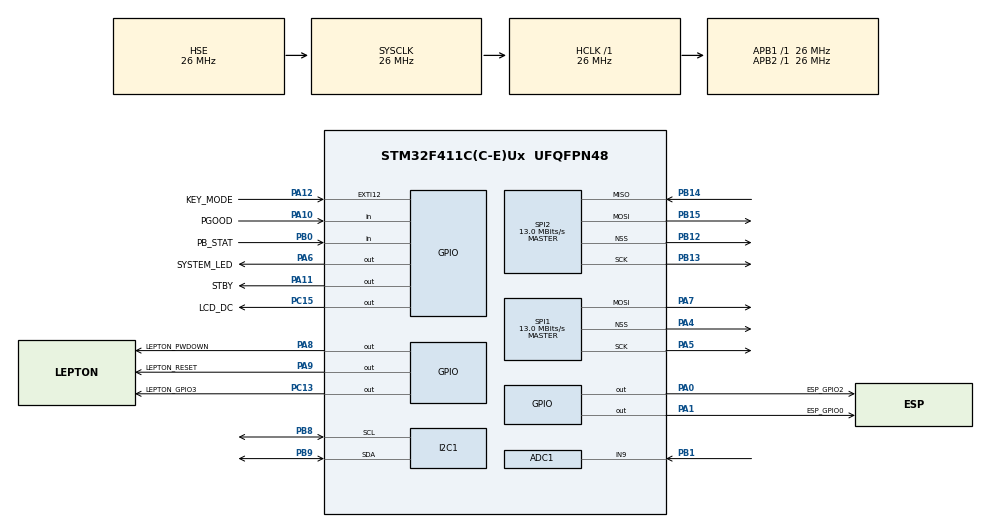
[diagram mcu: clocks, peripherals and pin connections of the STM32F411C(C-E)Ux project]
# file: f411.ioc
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ADC1.Channel-17\#ChannelRegularConversion=ADC_CHANNEL_9
ADC1.ClockPrescaler=ADC_CLOCK_SYNC_PCLK_DIV2
ADC1.ContinuousConvMode=DISABLE
ADC1.DMAContinuousRequests=DISABLE
ADC1.DataAlign=ADC_DATAALIGN_RIGHT
ADC1.DiscontinuousConvMode=DISABLE
ADC1.EOCSelection=ADC_EOC_SINGLE_CONV
ADC1.EnableAnalogWatchDog=false
ADC1.ExternalTrigConvEdge=ADC_EXTERNALTRIGCONVEDGE_NONE
ADC1.InjNumberOfConversion=0
ADC1.NbrOfConversion=1
ADC1.NbrOfConversionFlag=1
ADC1.Rank-17\#ChannelRegularConversion=1
ADC1.Resolution=ADC_RESOLUTION_12B
ADC1.SamplingTime-17\#ChannelRegularConversion=ADC_SAMPLETIME_3CYCLES
ADC1.ScanConvMode=DISABLE
ADC1.master=1
Dma.Request0=SPI2_TX
Dma.Request1=SPI1_TX
Dma.SPI1_TX.1.Direction=DMA_MEMORY_TO_PERIPH
Dma.SPI1_TX.1.FIFOMode=DMA_FIFOMODE_DISABLE
Dma.SPI1_TX.1.Instance=DMA2_Stream2
Dma.SPI1_TX.1.MemDataAlignment=DMA_MDATAALIGN_BYTE
Dma.SPI1_TX.1.MemInc=DMA_MINC_ENABLE
Dma.SPI1_TX.1.Mode=DMA_NORMAL
Dma.SPI1_TX.1.PeriphDataAlignment=DMA_PDATAALIGN_BYTE
Dma.SPI1_TX.1.PeriphInc=DMA_PINC_DISABLE
Dma.SPI1_TX.1.Priority=DMA_PRIORITY_LOW
Dma.SPI2_TX.0.Direction=DMA_MEMORY_TO_PERIPH
Dma.SPI2_TX.0.FIFOMode=DMA_FIFOMODE_DISABLE
Dma.SPI2_TX.0.Instance=DMA1_Stream4
Dma.SPI2_TX.0.MemDataAlignment=DMA_MDATAALIGN_HALFWORD
Dma.SPI2_TX.0.MemInc=DMA_MINC_ENABLE
Dma.SPI2_TX.0.Mode=DMA_NORMAL
Dma.SPI2_TX.0.PeriphDataAlignment=DMA_PDATAALIGN_HALFWORD
Dma.SPI2_TX.0.PeriphInc=DMA_PINC_DISABLE
Dma.SPI2_TX.0.Priority=DMA_PRIORITY_LOW
Mcu.Family=STM32F4
Mcu.Name=STM32F411C(C-E)Ux
Mcu.Package=UFQFPN48
NVIC.DMA1_Stream4_IRQn=true\:0\:0\:false\:false\:true
NVIC.DMA2_Stream2_IRQn=true\:0\:0\:false\:false\:true
NVIC.EXTI15_10_IRQn=true\:1\:2\:true\:false\:true
NVIC.PriorityGroup=NVIC_PRIORITYGROUP_2
NVIC.TIM2_IRQn=true\:2\:2\:true\:false\:true
PA0-WKUP.GPIO_Label=ESP_GPIO2
PA0-WKUP.Signal=GPIO_Output
PA1.GPIO_Label=ESP_GPIO0
PA1.Signal=GPIO_Output
PA10.GPIO_Label=PGOOD
PA10.Signal=GPIO_Input
PA11.GPIO_Label=STBY
PA11.Signal=GPIO_Output
PA12.GPIO_Label=KEY_MODE
PA12.GPIO_ModeDefaultEXTI=GPIO_MODE_IT_RISING_FALLING
PA12.GPIO_PuPd=GPIO_NOPULL
PA12.Signal=GPXTI12
PA13.Mode=Serial_Wire
PA13.Signal=SYS_JTMS-SWDIO
PA14.Mode=Serial_Wire
PA14.Signal=SYS_JTCK-SWCLK
PA4.Mode=NSS_Signal_Hard_Output
PA4.Signal=SPI1_NSS
PA5.Mode=TX_Only_Simplex_Unidirect_Master
PA5.Signal=SPI1_SCK
PA6.GPIO_Label=SYSTEM_LED
PA6.Signal=GPIO_Output
PA7.Mode=TX_Only_Simplex_Unidirect_Master
PA7.Signal=SPI1_MOSI
PA8.GPIO_Label=LEPTON_PWDOWN
PA8.Signal=GPIO_Output
PA9.GPIO_Label=LEPTON_RESET
PA9.Signal=GPIO_Output
PB0.GPIO_Label=PB_STAT
PB0.Signal=GPIO_Input
PB1.Signal=ADCx_IN9
PB12.Mode=NSS_Signal_Hard_Output
PB12.Signal=SPI2_NSS
PB13.Mode=Full_Duplex_Master
PB13.Signal=SPI2_SCK
PB14.Mode=Full_Duplex_Master
PB14.Signal=SPI2_MISO
PB15.Mode=Full_Duplex_Master
PB15.Signal=SPI2_MOSI
PB8.Mode=I2C
PB8.Signal=I2C1_SCL
PB9.Mode=I2C
PB9.Signal=I2C1_SDA
PC13-ANTI_TAMP.GPIO_Label=LEPTON_GPIO3
PC13-ANTI_TAMP.Signal=GPIO_Output
PC15-OSC32_OUT.GPIO_Label=LCD_DC
PC15-OSC32_OUT.Signal=GPIO_Output
PH0\ -\ OSC_IN.Mode=HSE-External-Oscillator
PH0\ -\ OSC_IN.Signal=RCC_OSC_IN
PH1\ -\ OSC_OUT.Mode=HSE-External-Oscillator
PH1\ -\ OSC_OUT.Signal=RCC_OSC_OUT
ProjectManager.HeapSize=0x200
ProjectManager.StackSize=0x400
ProjectManager.TargetToolchain=MDK-ARM V5
RCC.48MHZClocksFreq_Value=78000000
RCC.AHBFreq_Value=26000000
RCC.APB1Freq_Value=26000000
RCC.APB1TimFreq_Value=26000000
RCC.APB2Freq_Value=26000000
RCC.APB2TimFreq_Value=26000000
RCC.CortexFreq_Value=26000000
RCC.HCLKFreq_Value=26000000
RCC.HSE_VALUE=26000000
RCC.HSI_VALUE=16000000
RCC.LSE_VALUE=32768
RCC.PLLSourceVirtual=RCC_PLLSOURCE_HSE
RCC.SYSCLKFreq_VALUE=26000000
RCC.SYSCLKSource=RCC_SYSCLKSOURCE_HSE
RCC.VCOOutputFreq_Value=312000000
SH.ADCx_IN9.0=ADC1_IN9,IN9
SPI1.CalculateBaudRate=13.0 MBits/s
SPI1.Mode=SPI_MODE_MASTER
SPI1.VirtualNSS=VM_NSSHARD
SPI2.CLKPhase=SPI_PHASE_2EDGE
SPI2.CLKPolarity=SPI_POLARITY_HIGH
SPI2.CalculateBaudRate=13.0 MBits/s
SPI2.DataSize=SPI_DATASIZE_16BIT
SPI2.Mode=SPI_MODE_MASTER
SPI2.VirtualNSS=VM_NSSHARD
TIM2.Period=9
TIM2.Prescaler=2599
VP_IWDG_VS_IWDG.Mode=IWDG_Activate
VP_TIM2_VS_ClockSourceINT.Mode=Internal
board=f411

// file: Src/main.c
/**
  ******************************************************************************
  * File Name          : main.c
  * Description        : Main program body
  ******************************************************************************
  *
  * COPYRIGHT(c) 2016 STMicroelectronics
  *
  * Redistribution and use in source and binary forms, with or without modification,
  * are permitted provided that the following conditions are met:
  *   1. Redistributions of source code must retain the above copyright notice,
  *      this list of conditions and the following disclaimer.
  *   2. Redistributions in binary form must reproduce the above copyright notice,
  *      this list of conditions and the following disclaimer in the documentation
  *      and/or other materials provided with the distribution.
  *   3. Neither the name of STMicroelectronics nor the names of its contributors
  *      may be used to endorse or promote products derived from this software
  *      without specific prior written permission.
  *
  * THIS SOFTWARE IS PROVIDED BY THE COPYRIGHT HOLDERS AND CONTRIBUTORS "AS IS"
  * AND ANY EXPRESS OR IMPLIED WARRANTIES, INCLUDING, BUT NOT LIMITED TO, THE
  * IMPLIED WARRANTIES OF MERCHANTABILITY AND FITNESS FOR A PARTICULAR PURPOSE ARE
  * DISCLAIMED. IN NO EVENT SHALL THE COPYRIGHT HOLDER OR CONTRIBUTORS BE LIABLE
  * FOR ANY DIRECT, INDIRECT, INCIDENTAL, SPECIAL, EXEMPLARY, OR CONSEQUENTIAL
  * DAMAGES (INCLUDING, BUT NOT LIMITED TO, PROCUREMENT OF SUBSTITUTE GOODS OR
  * SERVICES; LOSS OF USE, DATA, OR PROFITS; OR BUSINESS INTERRUPTION) HOWEVER
  * CAUSED AND ON ANY THEORY OF LIABILITY, WHETHER IN CONTRACT, STRICT LIABILITY,
  * OR TORT (INCLUDING NEGLIGENCE OR OTHERWISE) ARISING IN ANY WAY OUT OF THE USE
  * OF THIS SOFTWARE, EVEN IF ADVISED OF THE POSSIBILITY OF SUCH DAMAGE.
  *
  ******************************************************************************
  */
#include "stm32f4xx_hal.h"

/* USER CODE BEGIN Includes */
#include "key.h"
/* USER CODE END Includes */

ADC_HandleTypeDef hadc1;

I2C_HandleTypeDef hi2c1;

IWDG_HandleTypeDef hiwdg;

SPI_HandleTypeDef hspi1;
SPI_HandleTypeDef hspi2;
DMA_HandleTypeDef hdma_spi1_tx;
DMA_HandleTypeDef hdma_spi2_tx;

TIM_HandleTypeDef htim2;

/* USER CODE BEGIN PV */
/* Private variables ---------------------------------------------------------*/

/* USER CODE END PV */

void SystemClock_Config(void);
void Error_Handler(void);
static void MX_GPIO_Init(void);
static void MX_DMA_Init(void);
static void MX_ADC1_Init(void);
static void MX_I2C1_Init(void);
static void MX_IWDG_Init(void);
static void MX_SPI1_Init(void);
static void MX_SPI2_Init(void);
static void MX_TIM2_Init(void);

/* USER CODE BEGIN PFP */
/* Private function prototypes -----------------------------------------------*/

/* USER CODE END PFP */

/* USER CODE BEGIN 0 */
extern uint8_t  Key_Up;
extern uint32_t Time_1ms;
/* USER CODE END 0 */

int main(void)
{

  /* USER CODE BEGIN 1 */
	KeyStatus Key_Value;
  /* USER CODE END 1 */

  /* MCU Configuration----------------------------------------------------------*/

  /* Reset of all peripherals, Initializes the Flash interface and the Systick. */
  HAL_Init();

  /* Configure the system clock */
  SystemClock_Config();

  /* Initialize all configured peripherals */
  MX_GPIO_Init();
  MX_DMA_Init();
  MX_ADC1_Init();
  MX_I2C1_Init();
  MX_IWDG_Init();
  MX_SPI1_Init();
  MX_SPI2_Init();
  MX_TIM2_Init();

  /* Infinite loop */
  while (1)
  {

  /* USER CODE BEGIN 3 */
		Key_Value = Key_Scan();
		if(Key_Value)
		{
			if(Key_Value == Key_Long)
			{
				                  // ���� ������������
			}

			if(Key_Value == Key_Short)
			{
			                    // ���� �̰���������
			}
		}
  }
  /* USER CODE END 3 */

}

/** System Clock Configuration
*/
void SystemClock_Config(void)
{

  RCC_OscInitTypeDef RCC_OscInitStruct;
  RCC_ClkInitTypeDef RCC_ClkInitStruct;

  __HAL_RCC_PWR_CLK_ENABLE();

  __HAL_PWR_VOLTAGESCALING_CONFIG(PWR_REGULATOR_VOLTAGE_SCALE1);

  RCC_OscInitStruct.OscillatorType = RCC_OSCILLATORTYPE_LSI|RCC_OSCILLATORTYPE_HSE;
  RCC_OscInitStruct.HSEState = RCC_HSE_ON;
  RCC_OscInitStruct.LSIState = RCC_LSI_ON;
  RCC_OscInitStruct.PLL.PLLState = RCC_PLL_NONE;
  if (HAL_RCC_OscConfig(&RCC_OscInitStruct) != HAL_OK)
  {
    Error_Handler();
  }

  RCC_ClkInitStruct.ClockType = RCC_CLOCKTYPE_HCLK|RCC_CLOCKTYPE_SYSCLK
                              |RCC_CLOCKTYPE_PCLK1|RCC_CLOCKTYPE_PCLK2;
  RCC_ClkInitStruct.SYSCLKSource = RCC_SYSCLKSOURCE_HSE;
  RCC_ClkInitStruct.AHBCLKDivider = RCC_SYSCLK_DIV1;
  RCC_ClkInitStruct.APB1CLKDivider = RCC_HCLK_DIV1;
  RCC_ClkInitStruct.APB2CLKDivider = RCC_HCLK_DIV1;
  if (HAL_RCC_ClockConfig(&RCC_ClkInitStruct, FLASH_LATENCY_0) != HAL_OK)
  {
    Error_Handler();
  }

  HAL_SYSTICK_Config(HAL_RCC_GetHCLKFreq()/1000);

  HAL_SYSTICK_CLKSourceConfig(SYSTICK_CLKSOURCE_HCLK);

  /* SysTick_IRQn interrupt configuration */
  HAL_NVIC_SetPriority(SysTick_IRQn, 0, 0);
}

/* ADC1 init function */
static void MX_ADC1_Init(void)
{

  ADC_ChannelConfTypeDef sConfig;

    /**Configure the global features of the ADC (Clock, Resolution, Data Alignment and number of conversion)
    */
  hadc1.Instance = ADC1;
  hadc1.Init.ClockPrescaler = ADC_CLOCK_SYNC_PCLK_DIV2;
  hadc1.Init.Resolution = ADC_RESOLUTION_12B;
  hadc1.Init.ScanConvMode = DISABLE;
  hadc1.Init.ContinuousConvMode = DISABLE;
  hadc1.Init.DiscontinuousConvMode = DISABLE;
  hadc1.Init.ExternalTrigConvEdge = ADC_EXTERNALTRIGCONVEDGE_NONE;
  hadc1.Init.DataAlign = ADC_DATAALIGN_RIGHT;
  hadc1.Init.NbrOfConversion = 1;
  hadc1.Init.DMAContinuousRequests = DISABLE;
  hadc1.Init.EOCSelection = ADC_EOC_SINGLE_CONV;
  if (HAL_ADC_Init(&hadc1) != HAL_OK)
  {
    Error_Handler();
  }

    /**Configure for the selected ADC regular channel its corresponding rank in the sequencer and its sample time.
    */
  sConfig.Channel = ADC_CHANNEL_9;
  sConfig.Rank = 1;
  sConfig.SamplingTime = ADC_SAMPLETIME_3CYCLES;
  if (HAL_ADC_ConfigChannel(&hadc1, &sConfig) != HAL_OK)
  {
    Error_Handler();
  }

}

/* I2C1 init function */
static void MX_I2C1_Init(void)
{

  hi2c1.Instance = I2C1;
  hi2c1.Init.ClockSpeed = 100000;
  hi2c1.Init.DutyCycle = I2C_DUTYCYCLE_2;
  hi2c1.Init.OwnAddress1 = 0;
  hi2c1.Init.AddressingMode = I2C_ADDRESSINGMODE_7BIT;
  hi2c1.Init.DualAddressMode = I2C_DUALADDRESS_DISABLE;
  hi2c1.Init.OwnAddress2 = 0;
  hi2c1.Init.GeneralCallMode = I2C_GENERALCALL_DISABLE;
  hi2c1.Init.NoStretchMode = I2C_NOSTRETCH_DISABLE;
  if (HAL_I2C_Init(&hi2c1) != HAL_OK)
  {
    Error_Handler();
  }

}

/* IWDG init function */
static void MX_IWDG_Init(void)
{

  hiwdg.Instance = IWDG;
  hiwdg.Init.Prescaler = IWDG_PRESCALER_4;
  hiwdg.Init.Reload = 4095;
  if (HAL_IWDG_Init(&hiwdg) != HAL_OK)
  {
    Error_Handler();
  }

}

/* SPI1 init function */
static void MX_SPI1_Init(void)
{

  hspi1.Instance = SPI1;
  hspi1.Init.Mode = SPI_MODE_MASTER;
  hspi1.Init.Direction = SPI_DIRECTION_2LINES;
  hspi1.Init.DataSize = SPI_DATASIZE_8BIT;
  hspi1.Init.CLKPolarity = SPI_POLARITY_LOW;
  hspi1.Init.CLKPhase = SPI_PHASE_1EDGE;
  hspi1.Init.NSS = SPI_NSS_HARD_OUTPUT;
  hspi1.Init.BaudRatePrescaler = SPI_BAUDRATEPRESCALER_2;
  hspi1.Init.FirstBit = SPI_FIRSTBIT_MSB;
  hspi1.Init.TIMode = SPI_TIMODE_DISABLE;
  hspi1.Init.CRCCalculation = SPI_CRCCALCULATION_DISABLE;
  hspi1.Init.CRCPolynomial = 10;
  if (HAL_SPI_Init(&hspi1) != HAL_OK)
  {
    Error_Handler();
  }

}

/* SPI2 init function */
static void MX_SPI2_Init(void)
{

  hspi2.Instance = SPI2;
  hspi2.Init.Mode = SPI_MODE_MASTER;
  hspi2.Init.Direction = SPI_DIRECTION_2LINES;
  hspi2.Init.DataSize = SPI_DATASIZE_16BIT;
  hspi2.Init.CLKPolarity = SPI_POLARITY_HIGH;
  hspi2.Init.CLKPhase = SPI_PHASE_2EDGE;
  hspi2.Init.NSS = SPI_NSS_HARD_OUTPUT;
  hspi2.Init.BaudRatePrescaler = SPI_BAUDRATEPRESCALER_2;
  hspi2.Init.FirstBit = SPI_FIRSTBIT_MSB;
  hspi2.Init.TIMode = SPI_TIMODE_DISABLE;
  hspi2.Init.CRCCalculation = SPI_CRCCALCULATION_DISABLE;
  hspi2.Init.CRCPolynomial = 10;
  if (HAL_SPI_Init(&hspi2) != HAL_OK)
  {
    Error_Handler();
  }

}

/* TIM2 init function */
static void MX_TIM2_Init(void)
{

  TIM_ClockConfigTypeDef sClockSourceConfig;
  TIM_MasterConfigTypeDef sMasterConfig;

  htim2.Instance = TIM2;
  htim2.Init.Prescaler = 2599;                  // 26MHz / 2600 = 10KHz     0.1ms
  htim2.Init.CounterMode = TIM_COUNTERMODE_UP;
  htim2.Init.Period = 9;                        // 0.1ms * 10 = 1ms
  htim2.Init.ClockDivision = TIM_CLOCKDIVISION_DIV1;
  if (HAL_TIM_Base_Init(&htim2) != HAL_OK)
  {
    Error_Handler();
  }

  sClockSourceConfig.ClockSource = TIM_CLOCKSOURCE_INTERNAL;
  if (HAL_TIM_ConfigClockSource(&htim2, &sClockSourceConfig) != HAL_OK)
  {
    Error_Handler();
  }

  sMasterConfig.MasterOutputTrigger = TIM_TRGO_RESET;
  sMasterConfig.MasterSlaveMode = TIM_MASTERSLAVEMODE_DISABLE;
  if (HAL_TIMEx_MasterConfigSynchronization(&htim2, &sMasterConfig) != HAL_OK)
  {
    Error_Handler();
  }

}

static void MX_DMA_Init(void)
{
  /* DMA controller clock enable */
  __HAL_RCC_DMA1_CLK_ENABLE();
  __HAL_RCC_DMA2_CLK_ENABLE();

  /* DMA interrupt init */
  /* DMA1_Stream4_IRQn interrupt configuration */
  HAL_NVIC_SetPriority(DMA1_Stream4_IRQn, 0, 0);
  HAL_NVIC_EnableIRQ(DMA1_Stream4_IRQn);
  /* DMA2_Stream2_IRQn interrupt configuration */
  HAL_NVIC_SetPriority(DMA2_Stream2_IRQn, 0, 0);
  HAL_NVIC_EnableIRQ(DMA2_Stream2_IRQn);

}

/** Configure pins as
        * Analog
        * Input
        * Output
        * EVENT_OUT
        * EXTI
*/
static void MX_GPIO_Init(void)
{

  GPIO_InitTypeDef GPIO_InitStruct;

  /* GPIO Ports Clock Enable */
  __HAL_RCC_GPIOC_CLK_ENABLE();
  __HAL_RCC_GPIOH_CLK_ENABLE();
  __HAL_RCC_GPIOA_CLK_ENABLE();
  __HAL_RCC_GPIOB_CLK_ENABLE();

  /*Configure GPIO pin Output Level */
  HAL_GPIO_WritePin(GPIOC, LEPTON_GPIO3_Pin|LCD_DC_Pin, GPIO_PIN_RESET);

  /*Configure GPIO pin Output Level */
  HAL_GPIO_WritePin(GPIOA, ESP_GPIO2_Pin|ESP_GPIO0_Pin|SYSTEM_LED_Pin|LEPTON_PWDOWN_Pin
                          |LEPTON_RESET_Pin|STBY_Pin, GPIO_PIN_RESET);

  /*Configure GPIO pins : LEPTON_GPIO3_Pin LCD_DC_Pin */
  GPIO_InitStruct.Pin = LEPTON_GPIO3_Pin|LCD_DC_Pin;
  GPIO_InitStruct.Mode = GPIO_MODE_OUTPUT_PP;
  GPIO_InitStruct.Pull = GPIO_NOPULL;
  GPIO_InitStruct.Speed = GPIO_SPEED_FREQ_LOW;
  HAL_GPIO_Init(GPIOC, &GPIO_InitStruct);

  /*Configure GPIO pins : ESP_GPIO2_Pin ESP_GPIO0_Pin SYSTEM_LED_Pin LEPTON_PWDOWN_Pin
                           LEPTON_RESET_Pin STBY_Pin */
  GPIO_InitStruct.Pin = ESP_GPIO2_Pin|ESP_GPIO0_Pin|SYSTEM_LED_Pin|LEPTON_PWDOWN_Pin
                          |LEPTON_RESET_Pin|STBY_Pin;
  GPIO_InitStruct.Mode = GPIO_MODE_OUTPUT_PP;
  GPIO_InitStruct.Pull = GPIO_NOPULL;
  GPIO_InitStruct.Speed = GPIO_SPEED_FREQ_LOW;
  HAL_GPIO_Init(GPIOA, &GPIO_InitStruct);

  /*Configure GPIO pin : PB_STAT_Pin */
  GPIO_InitStruct.Pin = PB_STAT_Pin;
  GPIO_InitStruct.Mode = GPIO_MODE_INPUT;
  GPIO_InitStruct.Pull = GPIO_NOPULL;
  HAL_GPIO_Init(PB_STAT_GPIO_Port, &GPIO_InitStruct);

  /*Configure GPIO pin : PGOOD_Pin */
  GPIO_InitStruct.Pin = PGOOD_Pin;
  GPIO_InitStruct.Mode = GPIO_MODE_INPUT;
  GPIO_InitStruct.Pull = GPIO_NOPULL;
  HAL_GPIO_Init(PGOOD_GPIO_Port, &GPIO_InitStruct);

  /*Configure GPIO pin : KEY_MODE_Pin */
  GPIO_InitStruct.Pin = KEY_MODE_Pin;
  GPIO_InitStruct.Mode = GPIO_MODE_IT_RISING_FALLING;
  GPIO_InitStruct.Pull = GPIO_NOPULL;
  HAL_GPIO_Init(KEY_MODE_GPIO_Port, &GPIO_InitStruct);

  /* EXTI interrupt init*/
  HAL_NVIC_SetPriority(EXTI15_10_IRQn, 1, 2);
  HAL_NVIC_EnableIRQ(EXTI15_10_IRQn);

}

void Error_Handler(void)
{
  while(1)
  {
  }
}

/************************ (C) COPYRIGHT STMicroelectronics *****END OF FILE****/
